# MCXC444 register map
Vendor: NXP Semiconductors; Series: MCX; File version: 1.6
CPU: CM0PLUS r0p0, little endian, no MPU, no FPU, VTOR, 2 interrupt priority bits
Registers are 32-bit, read-write, reset 0x0 unless marked. A register's access mark holds for its fields unless they carry their own. Offsets are from the block's base; [hi:lo] are bit positions; {n}, {i} and the like mark numbered series; 'fields as' and 'values as' point back to an identical list.

## TPM0 — Timer/PWM Module
Base 0x40038000; register names take the prefix TPM0_
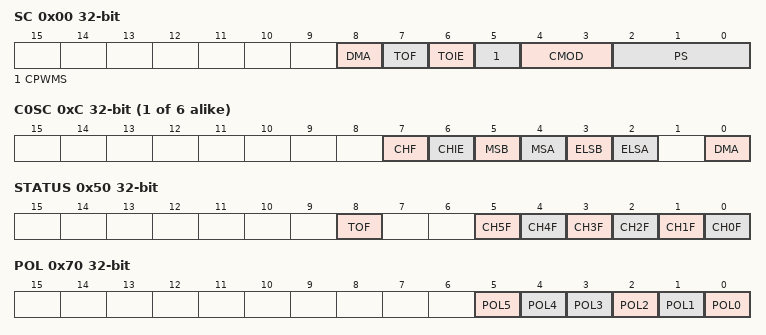
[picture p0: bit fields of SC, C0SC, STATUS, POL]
0x00 SC — Status and Control
  [8] DMA — DMA Enable
    0=b0 (Disables DMA transfers.); 1=b1 (Enables DMA transfers.)
  [7] TOF — Timer Overflow Flag
    0=b0 (TPM counter has not overflowed.); 1=b1 (TPM counter has overflowed.)
  [6] TOIE — Timer Overflow Interrupt Enable
    0=b0 (Disable TOF interrupts. Use software polling or DMA request.); 1=b1 (Enable TOF interrupts. An interrupt is generated when TOF equals one.)
  [5] CPWMS — Center-Aligned PWM Select
    0=b0 (TPM counter operates in up counting mode.); 1=b1 (TPM counter operates in up-down counting mode.)
  [4:3] CMOD — Clock Mode Selection
    0=b00 (TPM counter is disabled); 1=b01 (TPM counter increments on every TPM counter clock); 2=b10 (TPM counter increments on rising edge of TPM_EXTCLK synchronized to the TPM counter clock)
  [2:0] PS — Prescale Factor Selection
    0=b000 (Divide by 1); 1=b001 (Divide by 2); 2=b010 (Divide by 4); 3=b011 (Divide by 8); 4=b100 (Divide by 16); 5=b101 (Divide by 32); 6=b110 (Divide by 64); 7=b111 (Divide by 128)
0x04 CNT — Counter
  [15:0] COUNT — Counter value
0x08 MOD reset 0xFFFF — Modulo
  [15:0] MOD — Modulo value
{0xC+8i} C{i}SC (i=0..5) — Channel (n) Status and Control
  [7] CHF — Channel Flag
    0=b0 (No channel event has occurred.); 1=b1 (A channel event has occurred.)
  [6] CHIE — Channel Interrupt Enable
    0=b0 (Disable channel interrupts.); 1=b1 (Enable channel interrupts.)
  [5] MSB — Channel Mode Select
  [4] MSA — Channel Mode Select
  [3] ELSB — Edge or Level Select
  [2] ELSA — Edge or Level Select
  [0] DMA — DMA Enable
    0=b0 (Disable DMA transfers.); 1=b1 (Enable DMA transfers.)
{0x10+8i} C{i}V (i=0..5) — Channel (n) Value
  [15:0] VAL — Channel Value
0x50 STATUS — Capture and Compare Status
  [8] TOF — Timer Overflow Flag
    values as SC.TOF
  [n] CH{n}F (n=0..5) — Channel {n} Flag
    values as C0SC.CHF
0x70 POL — Channel Polarity
  [5] POL5 — Channel 5 Polarity
    0=b0 (The channel polarity is active high.); 1=b1 (The channel polarity is active low.)
  [4] POL4 — Channel Polarity 4
    0=b0 (The channel polarity is active high); 1=b1 (The channel polarity is active low.)
  [n] POL{n} (n=0..3) — Channel {n} Polarity
    values as POL5
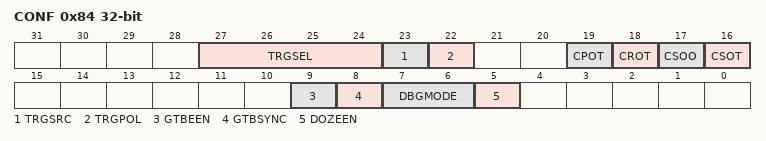
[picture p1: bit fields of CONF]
0x84 CONF — Configuration
  [27:24] TRGSEL — Trigger Select
    1=b0001 (Channel 0 pin input capture); 2=b0010 (Channel 1 pin input capture); 3=b0011 (Channel 0 or Channel 1 pin input capture); 4=b0100 (Channel 2 pin input capture); 5=b0101 (Channel 0 or Channel 2 pin input capture); 6=b0110 (Channel 1 or Channel 2 pin input capture); 7=b0111 (Channel 0 or Channel 1 or Channel 2 pin input capture); 8=b1000 (Channel 3 pin input capture); 9=b1001 (Channel 0 or Channel 3 pin input capture); 10=b1010 (Channel 1 or Channel 3 pin input capture); 11=b1011 (Channel 0 or Channel 1 or Channel 3 pin input capture); 12=b1100 (Channel 2 or Channel 3 pin input capture); 13=b1101 (Channel 0 or Channel 2 or Channel 3 pin input capture); 14=b1110 (Channel 1 or Channel 2 or Channel 3 pin input capture); 15=b1111 (Channel 0 or Channel 1 or Channel 2 or Channel 3 pin input capture)
  [23] TRGSRC — Trigger Source
    0=b0 (Trigger source selected by TRGSEL is external.); 1=b1 (Trigger source selected by TRGSEL is internal (channel pin input capture).)
  [22] TRGPOL — Trigger Polarity
    0=b0 (Trigger is active high.); 1=b1 (Trigger is active low.)
  [19] CPOT — Counter Pause On Trigger
  [18] CROT — Counter Reload On Trigger
    0=b0 (Counter is not reloaded due to a rising edge on the selected input trigger); 1=b1 (Counter is reloaded when a rising edge is detected on the selected input trigger)
  [17] CSOO — Counter Stop On Overflow
    0=b0 (TPM counter continues incrementing or decrementing after overflow); 1=b1 (TPM counter stops incrementing or decrementing after overflow.)
  [16] CSOT — Counter Start on Trigger
    0=b0 (TPM counter starts to increment immediately, once it is enabled.); 1=b1 (TPM counter only starts to increment when it a rising edge on the selected input trigger is detected, after it has been enabled or after it has stopped due to overflow.)
  [9] GTBEEN — Global time base enable
    0=b0 (All channels use the internally generated TPM counter as their timebase); 1=b1 (All channels use an externally generated global timebase as their timebase)
  [8] GTBSYNC — Global Time Base Synchronization
    0=b0 (Global timebase synchronization disabled.); 1=b1 (Global timebase synchronization enabled.)
  [7:6] DBGMODE — Debug Mode
    0=b00 (TPM counter is paused and does not increment during debug mode. Trigger inputs and input capture events are also ignored.); 3=b11 (TPM counter continues in debug mode.)
  [5] DOZEEN — Doze Enable
    0=b0 (Internal TPM counter continues in Doze mode.); 1=b1 (Internal TPM counter is paused and does not increment during Doze mode. Trigger inputs and input capture events are also ignored.)

## TPM1 — Timer/PWM Module
Base 0x40039000; register names take the prefix TPM1_
Registers as TPM0, without C*SC, C*V; these are added or differ:
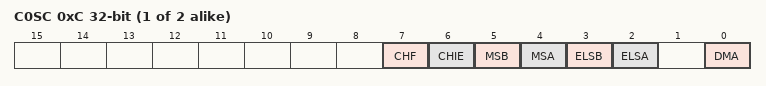
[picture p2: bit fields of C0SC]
{0xC+8i} C{i}SC (i=0..1) — Channel (n) Status and Control
  fields as TPM0.C0SC
{0x10+8i} C{i}V (i=0..1) — Channel (n) Value
  [15:0] VAL — Channel Value

## TPM2 — Timer/PWM Module
Base 0x4003A000; register names take the prefix TPM2_
Registers as TPM1.
